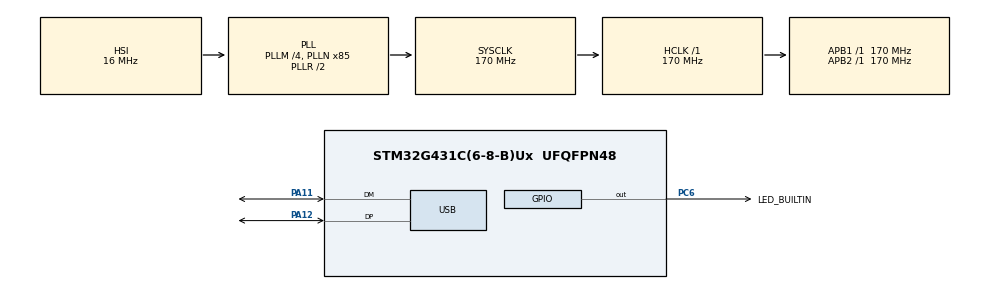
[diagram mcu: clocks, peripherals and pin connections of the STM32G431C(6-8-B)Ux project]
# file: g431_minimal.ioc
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Mcu.Family=STM32G4
Mcu.Name=STM32G431C(6-8-B)Ux
Mcu.Package=UFQFPN48
NVIC.PriorityGroup=NVIC_PRIORITYGROUP_4
NVIC.TIM6_DAC_IRQn=true\:15\:0\:false\:false\:true\:false\:false\:true\:true
NVIC.TimeBase=TIM6_DAC_IRQn
NVIC.TimeBaseIP=TIM6
NVIC.USB_LP_IRQn=true\:0\:0\:false\:false\:true\:false\:true\:true\:true
PA11.Mode=Device
PA11.Signal=USB_DM
PA12.Mode=Device
PA12.Signal=USB_DP
PA13.Mode=Serial_Wire
PA13.Signal=SYS_JTMS-SWDIO
PA14.Mode=Serial_Wire
PA14.Signal=SYS_JTCK-SWCLK
PC6.GPIO_Label=LED_BUILTIN
PC6.Signal=GPIO_Output
ProjectManager.HeapSize=0x200
ProjectManager.StackSize=0x400
ProjectManager.TargetToolchain=CMake
RCC.ADC12Freq_Value=170000000
RCC.AHBFreq_Value=170000000
RCC.APB1Freq_Value=170000000
RCC.APB1TimFreq_Value=170000000
RCC.APB2Freq_Value=170000000
RCC.APB2TimFreq_Value=170000000
RCC.CK48CLockSelection=RCC_USBCLKSOURCE_HSI48
RCC.CortexFreq_Value=170000000
RCC.EXTERNAL_CLOCK_VALUE=12288000
RCC.HCLKFreq_Value=170000000
RCC.HSE_VALUE=8000000
RCC.HSI48_VALUE=48000000
RCC.HSI_VALUE=16000000
RCC.LSE_VALUE=32768
RCC.PLLM=RCC_PLLM_DIV4
RCC.PLLN=85
RCC.SYSCLKFreq_VALUE=170000000
RCC.SYSCLKSource=RCC_SYSCLKSOURCE_PLLCLK
RCC.USBFreq_Value=48000000
RCC.VCOOutputFreq_Value=340000000
STMicroelectronics.X-CUBE-AZRTOS-G4.2.0.0.TX_ENABLE_STACK_CHECKING=1
STMicroelectronics.X-CUBE-AZRTOS-G4.2.0.0.ThreadXCcRTOSJjThreadXJjCore=true
STMicroelectronics.X-CUBE-AZRTOS-G4.2.0.0.USBD_CDCACM_EPINCMD_ADDR=2
STMicroelectronics.X-CUBE-AZRTOS-G4.2.0.0.USBXCcUSBJjUSBXJjCoreSystem=true
STMicroelectronics.X-CUBE-AZRTOS-G4.2.0.0.USBXCcUSBJjUSBXJjUXOoDeviceOoClassOoCDCOoACM=true
STMicroelectronics.X-CUBE-AZRTOS-G4.2.0.0.USBXCcUSBJjUSBXJjUXOoDeviceOoControllers=true
STMicroelectronics.X-CUBE-AZRTOS-G4.2.0.0.USBXCcUSBJjUSBXJjUXOoDeviceOoCoreStack=true
STMicroelectronics.X-CUBE-AZRTOS-G4.2.0.0.USBX_DEVICE_SYS_SIZE=6*1024
STMicroelectronics.X-CUBE-AZRTOS-G4.2.0.0.UX_DEVICE_APP_MEM_POOL_SIZE=11*1024
STMicroelectronics.X-CUBE-AZRTOS-G4.2.0.0.UX_SLAVE_REQUEST_DATA_MAX_LENGTH=512
STMicroelectronics.X-CUBE-AZRTOS-G4.2.0.0_IsAnAzureRtosMw=true
VP_RCC_VS_USB.Mode=USB_FS
VP_STMicroelectronics.X-CUBE-AZRTOS-G4_VS_RTOSJjThreadX_6.2.0_2.0.0.Mode=RTOSJjThreadX
VP_STMicroelectronics.X-CUBE-AZRTOS-G4_VS_USBJjUSBX_6.2.0_2.0.0.Mode=USBJjUSBX
VP_SYS_VS_DBSignals.Mode=DisableDeadBatterySignals
VP_SYS_VS_tim6.Mode=TIM6
board=custom

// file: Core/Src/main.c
/* USER CODE BEGIN Header */
/**
 ******************************************************************************
 * @file           : main.c
 * @brief          : Main program body
 ******************************************************************************
 * @attention
 *
 * Copyright (c) 2024 STMicroelectronics.
 * All rights reserved.
 *
 * This software is licensed under terms that can be found in the LICENSE file
 * in the root directory of this software component.
 * If no LICENSE file comes with this software, it is provided AS-IS.
 *
 ******************************************************************************
 */
/* USER CODE END Header */
#include "app_threadx.h"
#include "main.h"

/* USER CODE BEGIN Includes */
#include "ux_device_cdc_acm.h"
/* USER CODE END Includes */

PCD_HandleTypeDef hpcd_USB_FS;

/* USER CODE BEGIN PV */
extern UX_SLAVE_CLASS_CDC_ACM *cdc_acm;
/* USER CODE END PV */

void SystemClock_Config(void);
static void MX_GPIO_Init(void);

int main(void)
{

  /* MCU Configuration--------------------------------------------------------*/

  /* Reset of all peripherals, Initializes the Flash interface and the Systick. */
  HAL_Init();

  /* Configure the system clock */
  SystemClock_Config();

  /* Initialize all configured peripherals */
  MX_GPIO_Init();

  MX_ThreadX_Init();

  /* We should never get here as control is now taken by the scheduler */

  /* Infinite loop */
  while (1)
  {

  }
}

void SystemClock_Config(void)
{
  RCC_OscInitTypeDef RCC_OscInitStruct = {0};
  RCC_ClkInitTypeDef RCC_ClkInitStruct = {0};
  RCC_CRSInitTypeDef pInit = {0};

  /** Configure the main internal regulator output voltage
   */
  HAL_PWREx_ControlVoltageScaling(PWR_REGULATOR_VOLTAGE_SCALE1_BOOST);

  /** Initializes the RCC Oscillators according to the specified parameters
   * in the RCC_OscInitTypeDef structure.
   */
  RCC_OscInitStruct.OscillatorType = RCC_OSCILLATORTYPE_HSI | RCC_OSCILLATORTYPE_HSI48;
  RCC_OscInitStruct.HSIState = RCC_HSI_ON;
  RCC_OscInitStruct.HSICalibrationValue = RCC_HSICALIBRATION_DEFAULT;
  RCC_OscInitStruct.HSI48State = RCC_HSI48_ON;
  RCC_OscInitStruct.PLL.PLLState = RCC_PLL_ON;
  RCC_OscInitStruct.PLL.PLLSource = RCC_PLLSOURCE_HSI;
  RCC_OscInitStruct.PLL.PLLM = RCC_PLLM_DIV4;
  RCC_OscInitStruct.PLL.PLLN = 85;
  RCC_OscInitStruct.PLL.PLLP = RCC_PLLP_DIV2;
  RCC_OscInitStruct.PLL.PLLQ = RCC_PLLQ_DIV2;
  RCC_OscInitStruct.PLL.PLLR = RCC_PLLR_DIV2;
  if (HAL_RCC_OscConfig(&RCC_OscInitStruct) != HAL_OK)
  {
    Error_Handler();
  }

  /** Initializes the CPU, AHB and APB buses clocks
   */
  RCC_ClkInitStruct.ClockType = RCC_CLOCKTYPE_HCLK | RCC_CLOCKTYPE_SYSCLK | RCC_CLOCKTYPE_PCLK1 | RCC_CLOCKTYPE_PCLK2;
  RCC_ClkInitStruct.SYSCLKSource = RCC_SYSCLKSOURCE_PLLCLK;
  RCC_ClkInitStruct.AHBCLKDivider = RCC_SYSCLK_DIV1;
  RCC_ClkInitStruct.APB1CLKDivider = RCC_HCLK_DIV1;
  RCC_ClkInitStruct.APB2CLKDivider = RCC_HCLK_DIV1;

  if (HAL_RCC_ClockConfig(&RCC_ClkInitStruct, FLASH_LATENCY_4) != HAL_OK)
  {
    Error_Handler();
  }

  /** Enable the SYSCFG APB clock
   */
  __HAL_RCC_CRS_CLK_ENABLE();

  /** Configures CRS
   */
  pInit.Prescaler = RCC_CRS_SYNC_DIV1;
  pInit.Source = RCC_CRS_SYNC_SOURCE_USB;
  pInit.Polarity = RCC_CRS_SYNC_POLARITY_RISING;
  pInit.ReloadValue = __HAL_RCC_CRS_RELOADVALUE_CALCULATE(48000000, 1000);
  pInit.ErrorLimitValue = 34;
  pInit.HSI48CalibrationValue = 32;

  HAL_RCCEx_CRSConfig(&pInit);
}

void MX_USB_PCD_Init(void)
{

  hpcd_USB_FS.Instance = USB;
  hpcd_USB_FS.Init.dev_endpoints = 8;
  hpcd_USB_FS.Init.speed = PCD_SPEED_FULL;
  hpcd_USB_FS.Init.phy_itface = PCD_PHY_EMBEDDED;
  hpcd_USB_FS.Init.Sof_enable = DISABLE;
  hpcd_USB_FS.Init.low_power_enable = DISABLE;
  hpcd_USB_FS.Init.lpm_enable = DISABLE;
  hpcd_USB_FS.Init.battery_charging_enable = DISABLE;
  if (HAL_PCD_Init(&hpcd_USB_FS) != HAL_OK)
  {
    Error_Handler();
  }
}

static void MX_GPIO_Init(void)
{
  GPIO_InitTypeDef GPIO_InitStruct = {0};

  /* GPIO Ports Clock Enable */
  __HAL_RCC_GPIOC_CLK_ENABLE();
  __HAL_RCC_GPIOA_CLK_ENABLE();

  /*Configure GPIO pin Output Level */
  HAL_GPIO_WritePin(LED_BUILTIN_GPIO_Port, LED_BUILTIN_Pin, GPIO_PIN_RESET);

  /*Configure GPIO pin : LED_BUILTIN_Pin */
  GPIO_InitStruct.Pin = LED_BUILTIN_Pin;
  GPIO_InitStruct.Mode = GPIO_MODE_OUTPUT_PP;
  GPIO_InitStruct.Pull = GPIO_NOPULL;
  GPIO_InitStruct.Speed = GPIO_SPEED_FREQ_LOW;
  HAL_GPIO_Init(LED_BUILTIN_GPIO_Port, &GPIO_InitStruct);

}

/* USER CODE BEGIN 4 */
int _write(int file, char *ptr, int len)
{
  UNUSED(file);

  if (1 != cdc_acm->ux_slave_class_cdc_acm_data_dtr_state)
    return -1;

  int len_actual = 0;
  if (UX_SUCCESS != ux_device_class_cdc_acm_write(cdc_acm, (UCHAR *)ptr, (ULONG)len, (ULONG *)&len_actual))
    return -1;

  return len_actual;
}

int _read(int file, char *ptr, int len)
{
  UNUSED(file);

  if (1 != cdc_acm->ux_slave_class_cdc_acm_data_dtr_state)
    return -1;

  int len_actual = 0;
  if (UX_SUCCESS != ux_device_class_cdc_acm_read(cdc_acm, (UCHAR *)ptr, (ULONG)len, (ULONG *)&len_actual))
  {
    return -1;
  }

  return len_actual;
}
/* USER CODE END 4 */

void HAL_TIM_PeriodElapsedCallback(TIM_HandleTypeDef *htim)
{
  if (htim->Instance == TIM6)
  {
    HAL_IncTick();
  }
}

void Error_Handler(void)
{
  __disable_irq();
  while (1)
  {
  }
}
